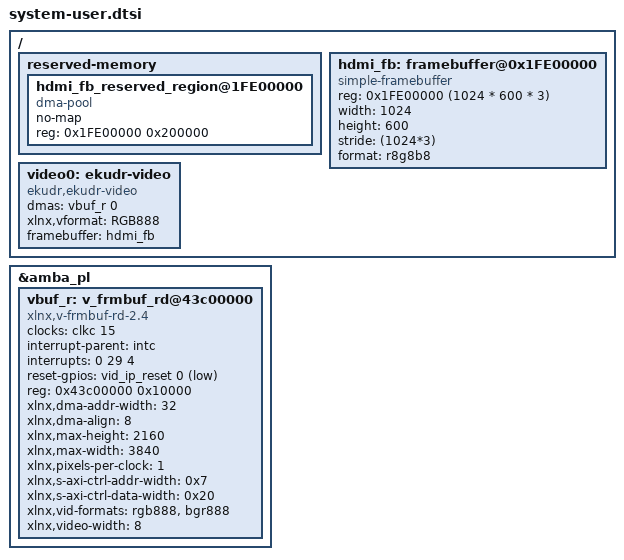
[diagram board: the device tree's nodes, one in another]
/include/ "system-conf.dtsi"
/ {
};

/ {
	#address-cells = <1>;
	#size-cells = <1>;

	reserved-memory {
		#address-cells = <1>;
		#size-cells = <1>;
		ranges;
		hdmi_fb_reserved_region@1FE00000 {
			compatible = "dma-pool";
			no-map;
			reg = <0x1FE00000 0x200000>;
		};
	};
};

&amba_pl {
	vbuf_r: v_frmbuf_rd@43c00000 {
                        #dma-cells = <1>;
                        clock-names = "ap_clk";
                        clocks = <&clkc 15>;
                        compatible = "xlnx,v-frmbuf-rd-2.4", "xlnx,axi-frmbuf-rd-v2.2";
                        interrupt-names = "interrupt";
                        interrupt-parent = <&intc>;
                        interrupts = <0 29 4>;
			reset-gpios = <&vid_ip_reset 0 1>;
                        reg = <0x43c00000 0x10000>;
                        xlnx,dma-addr-width = <32>;
                        xlnx,dma-align = <8>;
                        xlnx,max-height = <2160>;
                        xlnx,max-width = <3840>;
                        xlnx,pixels-per-clock = <1>;
                        xlnx,s-axi-ctrl-addr-width = <0x7>;
                        xlnx,s-axi-ctrl-data-width = <0x20>;
                        xlnx,vid-formats = "rgb888", "bgr888";
                        xlnx,video-width = <8>;
        };
/*
        v_tc_0: v_tc@43c10000 {
                clock-names = "clk", "s_axi_aclk";
                clocks = <&misc_clk_0>, <&clkc 15>;
                compatible = "xlnx,v-tc-6.1";
                reg = <0x43c10000 0x10000>;
		xlnx,pixels-per-clock = <1>;
		xlnx,generator ;		
        };
*/
};

/ {
	hdmi_fb: framebuffer@0x1FE00000 {
		compatible = "simple-framebuffer";
		reg = <0x1FE00000 (1024 * 600 * 3)>;
		width = <1024>;
		height = <600>;
		stride = <(1024*3)>;
		format = "r8g8b8";
		status = "okay";
	};

	video0: ekudr-video {
		compatible = "ekudr,ekudr-video";
		dmas = <&vbuf_r 0>;
		dma-names = "dma0";
		xlnx,vformat = "RGB888";
		framebuffer = <&hdmi_fb>;
	}; 
};
